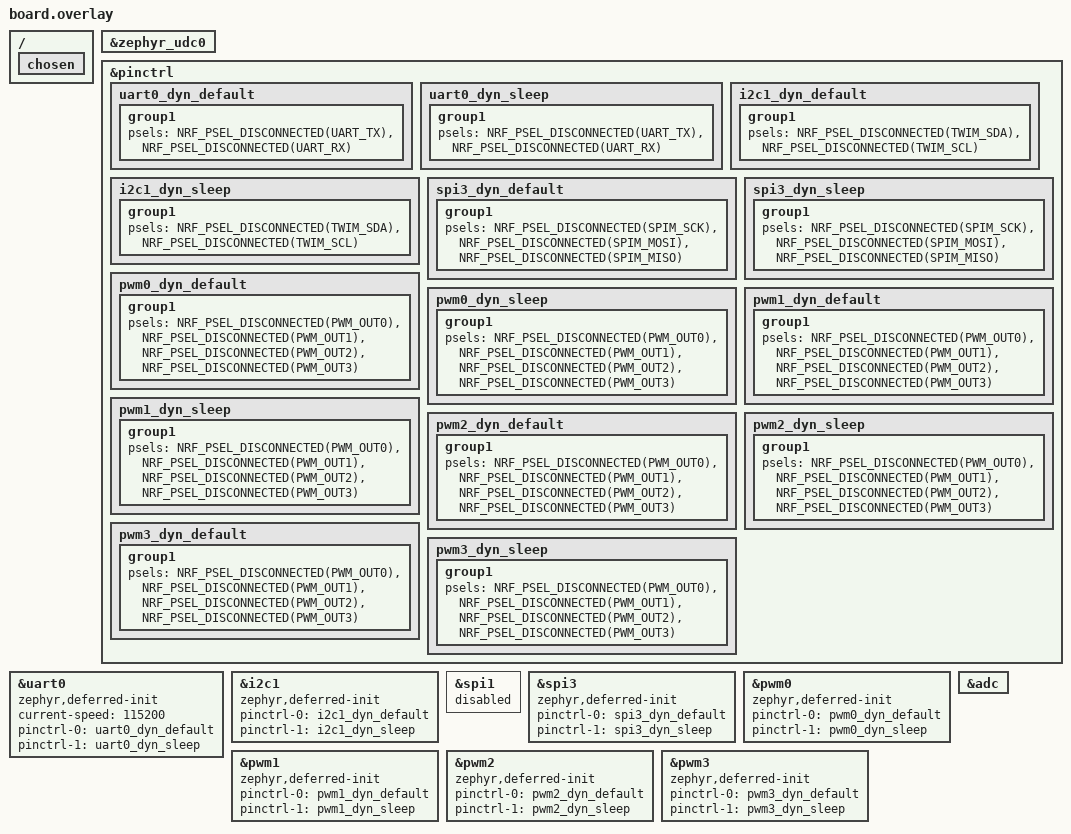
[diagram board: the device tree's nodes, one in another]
/* Partition layout is owned by the mcuboot fork
 * (dts/adafruit/adafruit_clue_nrf52840.dtsi) and applied to this image by
 * sysbuild. This overlay only adds board/app config. */
/ {
	chosen {
		/delete-property/ zephyr,console;
		/delete-property/ zephyr,shell-uart;
		/delete-property/ zephyr,uart-mcumgr;
		/delete-property/ zephyr,bt-mon-uart;
		/delete-property/ zephyr,bt-c2h-uart;
	};
};

&zephyr_udc0 {
	/delete-node/ board_cdc_acm_uart;
};

// UART0, I2C1 and SPI3 are enabled with all pins disconnected and marked
// zephyr,deferred-init so nothing is claimed at boot: the iobroker
// initializes and routes a device to arbitrary pins when a busio object is
// constructed, and de-initializes it on release. (I2C0 is the fixed sensor
// bus, SPI2 the fixed display bus, and QSPI the fixed external flash.)
//
// I2C1 and SPI1 are the same peripheral instance (0x40004000), so only one
// mode can be enabled: I2C is the more useful dynamic bus on the CLUE.
// SPI1 is left disabled; UART1 is enabled by neither overlay because UART0
// already provides a dynamic serial instance.

&pinctrl {
	uart0_dyn_default: uart0_dyn_default {
		group1 {
			psels = <NRF_PSEL_DISCONNECTED(UART_TX)>,
				<NRF_PSEL_DISCONNECTED(UART_RX)>;
		};
	};

	uart0_dyn_sleep: uart0_dyn_sleep {
		group1 {
			psels = <NRF_PSEL_DISCONNECTED(UART_TX)>,
				<NRF_PSEL_DISCONNECTED(UART_RX)>;
		};
	};

	i2c1_dyn_default: i2c1_dyn_default {
		group1 {
			psels = <NRF_PSEL_DISCONNECTED(TWIM_SDA)>,
				<NRF_PSEL_DISCONNECTED(TWIM_SCL)>;
		};
	};

	i2c1_dyn_sleep: i2c1_dyn_sleep {
		group1 {
			psels = <NRF_PSEL_DISCONNECTED(TWIM_SDA)>,
				<NRF_PSEL_DISCONNECTED(TWIM_SCL)>;
		};
	};

	spi3_dyn_default: spi3_dyn_default {
		group1 {
			psels = <NRF_PSEL_DISCONNECTED(SPIM_SCK)>,
				<NRF_PSEL_DISCONNECTED(SPIM_MOSI)>,
				<NRF_PSEL_DISCONNECTED(SPIM_MISO)>;
		};
	};

	spi3_dyn_sleep: spi3_dyn_sleep {
		group1 {
			psels = <NRF_PSEL_DISCONNECTED(SPIM_SCK)>,
				<NRF_PSEL_DISCONNECTED(SPIM_MOSI)>,
				<NRF_PSEL_DISCONNECTED(SPIM_MISO)>;
		};
	};

	pwm0_dyn_default: pwm0_dyn_default {
		group1 {
			psels = <NRF_PSEL_DISCONNECTED(PWM_OUT0)>,
				<NRF_PSEL_DISCONNECTED(PWM_OUT1)>,
				<NRF_PSEL_DISCONNECTED(PWM_OUT2)>,
				<NRF_PSEL_DISCONNECTED(PWM_OUT3)>;
		};
	};

	pwm0_dyn_sleep: pwm0_dyn_sleep {
		group1 {
			psels = <NRF_PSEL_DISCONNECTED(PWM_OUT0)>,
				<NRF_PSEL_DISCONNECTED(PWM_OUT1)>,
				<NRF_PSEL_DISCONNECTED(PWM_OUT2)>,
				<NRF_PSEL_DISCONNECTED(PWM_OUT3)>;
		};
	};

	pwm1_dyn_default: pwm1_dyn_default {
		group1 {
			psels = <NRF_PSEL_DISCONNECTED(PWM_OUT0)>,
				<NRF_PSEL_DISCONNECTED(PWM_OUT1)>,
				<NRF_PSEL_DISCONNECTED(PWM_OUT2)>,
				<NRF_PSEL_DISCONNECTED(PWM_OUT3)>;
		};
	};

	pwm1_dyn_sleep: pwm1_dyn_sleep {
		group1 {
			psels = <NRF_PSEL_DISCONNECTED(PWM_OUT0)>,
				<NRF_PSEL_DISCONNECTED(PWM_OUT1)>,
				<NRF_PSEL_DISCONNECTED(PWM_OUT2)>,
				<NRF_PSEL_DISCONNECTED(PWM_OUT3)>;
		};
	};

	pwm2_dyn_default: pwm2_dyn_default {
		group1 {
			psels = <NRF_PSEL_DISCONNECTED(PWM_OUT0)>,
				<NRF_PSEL_DISCONNECTED(PWM_OUT1)>,
				<NRF_PSEL_DISCONNECTED(PWM_OUT2)>,
				<NRF_PSEL_DISCONNECTED(PWM_OUT3)>;
		};
	};

	pwm2_dyn_sleep: pwm2_dyn_sleep {
		group1 {
			psels = <NRF_PSEL_DISCONNECTED(PWM_OUT0)>,
				<NRF_PSEL_DISCONNECTED(PWM_OUT1)>,
				<NRF_PSEL_DISCONNECTED(PWM_OUT2)>,
				<NRF_PSEL_DISCONNECTED(PWM_OUT3)>;
		};
	};

	pwm3_dyn_default: pwm3_dyn_default {
		group1 {
			psels = <NRF_PSEL_DISCONNECTED(PWM_OUT0)>,
				<NRF_PSEL_DISCONNECTED(PWM_OUT1)>,
				<NRF_PSEL_DISCONNECTED(PWM_OUT2)>,
				<NRF_PSEL_DISCONNECTED(PWM_OUT3)>;
		};
	};

	pwm3_dyn_sleep: pwm3_dyn_sleep {
		group1 {
			psels = <NRF_PSEL_DISCONNECTED(PWM_OUT0)>,
				<NRF_PSEL_DISCONNECTED(PWM_OUT1)>,
				<NRF_PSEL_DISCONNECTED(PWM_OUT2)>,
				<NRF_PSEL_DISCONNECTED(PWM_OUT3)>;
		};
	};
};

&uart0 {
	status = "okay";
	zephyr,deferred-init;
	current-speed = <115200>;
	pinctrl-0 = <&uart0_dyn_default>;
	pinctrl-1 = <&uart0_dyn_sleep>;
	pinctrl-names = "default", "sleep";
};

&i2c1 {
	status = "okay";
	zephyr,deferred-init;
	pinctrl-0 = <&i2c1_dyn_default>;
	pinctrl-1 = <&i2c1_dyn_sleep>;
	pinctrl-names = "default", "sleep";
};

// SPI1 shares the 0x40004000 instance with I2C1, which is enabled above, so
// leave SPI1 disabled.
&spi1 {
	status = "disabled";
};

&spi3 {
	status = "okay";
	zephyr,deferred-init;
	pinctrl-0 = <&spi3_dyn_default>;
	pinctrl-1 = <&spi3_dyn_sleep>;
	pinctrl-names = "default", "sleep";
};

// PWM instances, same scheme: all four outputs disconnected and deferred
// init, so iobroker can hand an instance to neopixel_write and pwmio and
// route its outputs at runtime.

&pwm0 {
	status = "okay";
	zephyr,deferred-init;
	pinctrl-0 = <&pwm0_dyn_default>;
	pinctrl-1 = <&pwm0_dyn_sleep>;
	pinctrl-names = "default", "sleep";
};

&pwm1 {
	status = "okay";
	zephyr,deferred-init;
	pinctrl-0 = <&pwm1_dyn_default>;
	pinctrl-1 = <&pwm1_dyn_sleep>;
	pinctrl-names = "default", "sleep";
};

&pwm2 {
	status = "okay";
	zephyr,deferred-init;
	pinctrl-0 = <&pwm2_dyn_default>;
	pinctrl-1 = <&pwm2_dyn_sleep>;
	pinctrl-names = "default", "sleep";
};

&pwm3 {
	status = "okay";
	zephyr,deferred-init;
	pinctrl-0 = <&pwm3_dyn_default>;
	pinctrl-1 = <&pwm3_dyn_sleep>;
	pinctrl-names = "default", "sleep";
};

#include "../../../app.overlay"

/* Enable the SAADC for analogio (AIN0..AIN7 are on P0.02..P0.05 and P0.28..P0.31). */
&adc {
	status = "okay";
};
